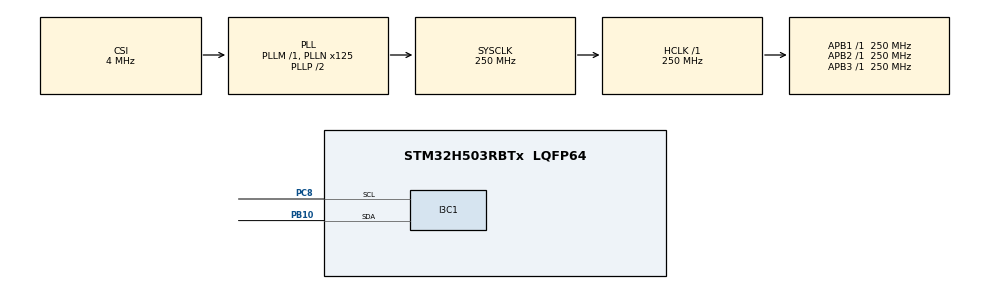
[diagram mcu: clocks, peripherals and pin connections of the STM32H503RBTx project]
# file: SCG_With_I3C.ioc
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BOOTPATH.BootPathName=LEGACY
BOOTPATH.UserSelectedBootPath=LEGACY
I3C1.BusFreeDuration=402
I3C1.DutyCycleI3C=50
I3C1.FrequencyI3C=3000
I3C1.Register0=0x00592928
I3C1.Register1=0x103200f8
I3C1.SCLI3CHighDuration=0x29
I3C1.SCLODLowDuration=0x59
I3C1.SCLPPLowDuration=0x28
I3C1.SCL_OD_Freq=1894
I3C1.SCL_PP_Freq=3012
I3C1.SDAHoldTime=HAL_I3C_SDA_HOLD_TIME_1_5
I3C1.SDARiseTime=350
I3C1.hexBusFreeDuration=0x32
I3C1.hexBusIdleDuration=0xf8
Mcu.Family=STM32H5
Mcu.Name=STM32H503RBTx
Mcu.Package=LQFP64
NUCLEO-H503RB.BUTTON=1
NUCLEO-H503RB.LD2=true
NUCLEO-H503RB.VCP=true
NVIC.EXTI13_IRQn=true\:0\:0\:false\:false\:true\:false\:true\:true
NVIC.I3C1_ER_IRQn=true\:0\:0\:false\:false\:true\:true\:true\:true
NVIC.I3C1_EV_IRQn=true\:0\:0\:false\:false\:true\:true\:true\:true
NVIC.PriorityGroup=NVIC_PRIORITYGROUP_4
PB10.GPIO_Pu=GPIO_PULLUP
PB10.Mode=Controller
PB10.Signal=I3C1_SDA
PB2.Mode=Clock-out-LSCO
PB2.Signal=RCC_LSCO
PC8.Mode=Controller
PC8.Signal=I3C1_SCL
ProjectManager.HeapSize=0x200
ProjectManager.StackSize=0x400
ProjectManager.TargetToolchain=STM32CubeIDE
RCC.ADCFreq_Value=250000000
RCC.AHBFreq_Value=250000000
RCC.APB1Freq_Value=250000000
RCC.APB1TimFreq_Value=250000000
RCC.APB2Freq_Value=250000000
RCC.APB2TimFreq_Value=250000000
RCC.APB3Freq_Value=250000000
RCC.CSI_VALUE=4000000
RCC.CortexFreq_Value=250000000
RCC.EPOD_VALUE=4000000
RCC.HCLKFreq_Value=250000000
RCC.HSE_VALUE=24000000
RCC.HSI48_VALUE=48000000
RCC.HSIDiv=RCC_HSI_DIV1
RCC.HSI_VALUE=64000000
RCC.LSE_VALUE=32768
RCC.LSIRC_VALUE=32000
RCC.PLL2FRACN=0
RCC.PLLFRACN=0
RCC.PLLN=125
RCC.RCC_MCO1Source=RCC_MCO1SOURCE_HSI48
RCC.RCC_MCODiv=RCC_MCODIV_2
RCC.SYSCLKFreq_VALUE=250000000
RCC.SYSCLKSource=RCC_SYSCLKSOURCE_PLLCLK
RCC.USBFreq_Value=48000000
RCC.VCOOutputFreq_Value=500000000
VP_BOOTPATH_VS_BOOTPATH.Mode=BP_Activate
VP_CORTEX_M33_NS_VS_Hclk.Mode=Hclk_Mode
VP_ICACHE_VS_ICACHE.Mode=DefaultMode
VP_MEMORYMAP_VS_MEMORYMAP.Mode=CurAppReg
VP_NUCLEO-H503RB_VS_BSP_COMMON.Mode=COMMON
VP_PWR_VS_DBSignals.Mode=DisableDeadBatterySignals
VP_PWR_VS_LPOM.Mode=PowerOptimisation
VP_PWR_VS_SECSignals.Mode=Security/Privilege
board=NUCLEO-H503RB

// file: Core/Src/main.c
/* USER CODE BEGIN Header */
/**
  ******************************************************************************
  * @file           : main.c
  * @brief          : Main program body
  ******************************************************************************
  * @attention
  *
  * Copyright (c) 2025 STMicroelectronics.
  * All rights reserved.
  *
  * This software is licensed under terms that can be found in the LICENSE file
  * in the root directory of this software component.
  * If no LICENSE file comes with this software, it is provided AS-IS.
  *
  ******************************************************************************
  */
/* USER CODE END Header */
#include "main.h"

/* USER CODE BEGIN PD */
#define I3C_BROADCAST_ADDR      0x7E
#define ENTDAA_CCC              0x07  // ENTDAA CCC code
/* USER CODE END PD */

COM_InitTypeDef BspCOMInit;

I3C_HandleTypeDef hi3c1;

void SystemClock_Config(void);
static void MX_GPIO_Init(void);
static void MX_I3C1_Init(void);
static void MX_ICACHE_Init(void);

int main(void)
{

  /* MCU Configuration--------------------------------------------------------*/

  /* Reset of all peripherals, Initializes the Flash interface and the Systick. */
  HAL_Init();

  /* Configure the system clock */
  SystemClock_Config();

  /* Initialize all configured peripherals */
  MX_GPIO_Init();
  MX_I3C1_Init();
  MX_ICACHE_Init();

  /* Initialize led */
  BSP_LED_Init(LED_GREEN);

  /* Initialize USER push-button, will be used to trigger an interrupt each time it's pressed.*/
  BSP_PB_Init(BUTTON_USER, BUTTON_MODE_EXTI);

  /* USER CODE BEGIN 2 */
  HAL_StatusTypeDef status = HAL_OK;
  uint64_t TargetPayload[2] = {0,0};
  uint8_t dynamic_adr[2] = {0x32,0x33};
  uint8_t i = 0;

  /* Wait for USER push-button press before starting the Communication */
    while (BSP_PB_GetState(BUTTON_USER) != GPIO_PIN_RESET)
    {
    }

    /* Wait for USER push-button release before starting the Communication */
    while (BSP_PB_GetState(BUTTON_USER) != GPIO_PIN_SET)
    {
    }
  do
        {
	  	  status = HAL_I3C_Ctrl_DynAddrAssign(&hi3c1, &TargetPayload[i], I3C_ONLY_ENTDAA, 5000);
          if (status == HAL_BUSY)
          {
            status = HAL_I3C_Ctrl_SetDynAddr(&hi3c1, dynamic_adr[i]);
            status = HAL_BUSY;
          }
          i++;
        } while (status == HAL_BUSY);
  /* USER CODE END 2 */

  /* Initialize COM1 port (115200, 8 bits (7-bit data + 1 stop bit), no parity */
  BspCOMInit.BaudRate   = 115200;
  BspCOMInit.WordLength = COM_WORDLENGTH_8B;
  BspCOMInit.StopBits   = COM_STOPBITS_1;
  BspCOMInit.Parity     = COM_PARITY_NONE;
  BspCOMInit.HwFlowCtl  = COM_HWCONTROL_NONE;
  if (BSP_COM_Init(COM1, &BspCOMInit) != BSP_ERROR_NONE)
  {
    Error_Handler();
  }

  /* Infinite loop */
  while (1)
  {

  }
}

void SystemClock_Config(void)
{
  RCC_OscInitTypeDef RCC_OscInitStruct = {0};
  RCC_ClkInitTypeDef RCC_ClkInitStruct = {0};

  /** Configure the main internal regulator output voltage
  */
  __HAL_PWR_VOLTAGESCALING_CONFIG(PWR_REGULATOR_VOLTAGE_SCALE0);

  while(!__HAL_PWR_GET_FLAG(PWR_FLAG_VOSRDY)) {}

  /** Initializes the RCC Oscillators according to the specified parameters
  * in the RCC_OscInitTypeDef structure.
  */
  RCC_OscInitStruct.OscillatorType = RCC_OSCILLATORTYPE_LSI|RCC_OSCILLATORTYPE_CSI;
  RCC_OscInitStruct.LSIState = RCC_LSI_ON;
  RCC_OscInitStruct.CSIState = RCC_CSI_ON;
  RCC_OscInitStruct.CSICalibrationValue = RCC_CSICALIBRATION_DEFAULT;
  RCC_OscInitStruct.PLL.PLLState = RCC_PLL_ON;
  RCC_OscInitStruct.PLL.PLLSource = RCC_PLL1_SOURCE_CSI;
  RCC_OscInitStruct.PLL.PLLM = 1;
  RCC_OscInitStruct.PLL.PLLN = 125;
  RCC_OscInitStruct.PLL.PLLP = 2;
  RCC_OscInitStruct.PLL.PLLQ = 2;
  RCC_OscInitStruct.PLL.PLLR = 2;
  RCC_OscInitStruct.PLL.PLLRGE = RCC_PLL1_VCIRANGE_2;
  RCC_OscInitStruct.PLL.PLLVCOSEL = RCC_PLL1_VCORANGE_WIDE;
  RCC_OscInitStruct.PLL.PLLFRACN = 0;
  if (HAL_RCC_OscConfig(&RCC_OscInitStruct) != HAL_OK)
  {
    Error_Handler();
  }

  /** Initializes the CPU, AHB and APB buses clocks
  */
  RCC_ClkInitStruct.ClockType = RCC_CLOCKTYPE_HCLK|RCC_CLOCKTYPE_SYSCLK
                              |RCC_CLOCKTYPE_PCLK1|RCC_CLOCKTYPE_PCLK2
                              |RCC_CLOCKTYPE_PCLK3;
  RCC_ClkInitStruct.SYSCLKSource = RCC_SYSCLKSOURCE_PLLCLK;
  RCC_ClkInitStruct.AHBCLKDivider = RCC_SYSCLK_DIV1;
  RCC_ClkInitStruct.APB1CLKDivider = RCC_HCLK_DIV1;
  RCC_ClkInitStruct.APB2CLKDivider = RCC_HCLK_DIV1;
  RCC_ClkInitStruct.APB3CLKDivider = RCC_HCLK_DIV1;

  if (HAL_RCC_ClockConfig(&RCC_ClkInitStruct, FLASH_LATENCY_5) != HAL_OK)
  {
    Error_Handler();
  }

  /** LSCO configuration
  */
  HAL_RCCEx_EnableLSCO(RCC_LSCOSOURCE_LSI);

  /** Configure the programming delay
  */
  __HAL_FLASH_SET_PROGRAM_DELAY(FLASH_PROGRAMMING_DELAY_2);
}

static void MX_I3C1_Init(void)
{

  I3C_FifoConfTypeDef sFifoConfig = {0};
  I3C_CtrlConfTypeDef sCtrlConfig = {0};

  hi3c1.Instance = I3C1;
  hi3c1.Mode = HAL_I3C_MODE_CONTROLLER;
  hi3c1.Init.CtrlBusCharacteristic.SDAHoldTime = HAL_I3C_SDA_HOLD_TIME_1_5;
  hi3c1.Init.CtrlBusCharacteristic.WaitTime = HAL_I3C_OWN_ACTIVITY_STATE_0;
  hi3c1.Init.CtrlBusCharacteristic.SCLPPLowDuration = 0x28;
  hi3c1.Init.CtrlBusCharacteristic.SCLI3CHighDuration = 0x29;
  hi3c1.Init.CtrlBusCharacteristic.SCLODLowDuration = 0x59;
  hi3c1.Init.CtrlBusCharacteristic.SCLI2CHighDuration = 0x00;
  hi3c1.Init.CtrlBusCharacteristic.BusFreeDuration = 0x32;
  hi3c1.Init.CtrlBusCharacteristic.BusIdleDuration = 0xf8;
  if (HAL_I3C_Init(&hi3c1) != HAL_OK)
  {
    Error_Handler();
  }

  /** Configure FIFO
  */
  sFifoConfig.RxFifoThreshold = HAL_I3C_RXFIFO_THRESHOLD_1_4;
  sFifoConfig.TxFifoThreshold = HAL_I3C_TXFIFO_THRESHOLD_1_4;
  sFifoConfig.ControlFifo = HAL_I3C_CONTROLFIFO_DISABLE;
  sFifoConfig.StatusFifo = HAL_I3C_STATUSFIFO_DISABLE;
  if (HAL_I3C_SetConfigFifo(&hi3c1, &sFifoConfig) != HAL_OK)
  {
    Error_Handler();
  }

  /** Configure controller
  */
  sCtrlConfig.DynamicAddr = 0;
  sCtrlConfig.StallTime = 0x00;
  sCtrlConfig.HotJoinAllowed = DISABLE;
  sCtrlConfig.ACKStallState = DISABLE;
  sCtrlConfig.CCCStallState = DISABLE;
  sCtrlConfig.TxStallState = DISABLE;
  sCtrlConfig.RxStallState = DISABLE;
  sCtrlConfig.HighKeeperSDA = DISABLE;
  if (HAL_I3C_Ctrl_Config(&hi3c1, &sCtrlConfig) != HAL_OK)
  {
    Error_Handler();
  }

}

static void MX_ICACHE_Init(void)
{

  /** Enable instruction cache (default 2-ways set associative cache)
  */
  if (HAL_ICACHE_Enable() != HAL_OK)
  {
    Error_Handler();
  }

}

static void MX_GPIO_Init(void)
{
  GPIO_InitTypeDef GPIO_InitStruct = {0};

  /* GPIO Ports Clock Enable */
  __HAL_RCC_GPIOB_CLK_ENABLE();
  __HAL_RCC_GPIOC_CLK_ENABLE();

  /*Configure GPIO pin : PB2 */
  GPIO_InitStruct.Pin = GPIO_PIN_2;
  GPIO_InitStruct.Mode = GPIO_MODE_ANALOG;
  GPIO_InitStruct.Pull = GPIO_NOPULL;
  HAL_GPIO_Init(GPIOB, &GPIO_InitStruct);

}

void Error_Handler(void)
{
  __disable_irq();
  while (1)
  {
  }
}
